# mdio_master_model: IP-XACT component
VLNV IcronTechnologies:IcronTechnologies:mdio_master_model:1.0

## Parameters
addr_width = 8
bus_width = 32

## Bus interfaces (logical=physical port)
default_map: slave AGNISYS:AGNISYS:APB:1.0, memory map mdio_mastermap
  pclk=pclk, presetn=presetn, psel=psel, penable=penable, pwrite=pwrite, pprot=pprot, pstrb=pstrb, pwdata=pwdata, paddr=paddr, pready=pready, prdata=prdata, pslverr=pslverr

## Ports
in pclk
in presetn
in psel
in penable
in pwrite
in pprot[2:0]
in pstrb[(bus_width div 8 )-1:0]
in pwdata[bus_width -1:0]
in paddr[addr_width -1:0]
out pready
out prdata[bus_width -1:0]
out pslverr
out mdio_master_regsversion_major_r[7:0]
out mdio_master_regsversion_minor_r[7:0]
out mdio_master_regsversion_patch_r[7:0]
out mdio_master_regstiming_enb
out mdio_master_regstiming_hold_clks_r[7:0]
out mdio_master_regstiming_setup_clks_r[7:0]
out mdio_master_regstiming_half_mdc_clks_r[7:0]
out mdio_master_regscontrol_enb
out mdio_master_regscontrol_phyad_r[4:0]
out mdio_master_regscontrol_regad_r[4:0]
out mdio_master_regscontrol_op_r[1:0]
out mdio_master_regscontrol_st_r[1:0]
out mdio_master_regscontrol_go_r
in mdio_master_regscontrol_go_hw_clear
out mdio_master_regswr_data_enb
out mdio_master_regswr_data_wr_data_r[15:0]
in mdio_master_regsrd_data_rd_data_in[15:0]
in mdio_master_regsrd_data_rd_data_in_enb

## Address spaces and blocks
mdio_mastermap.mdio_master: base 0x000, range 0x100, width 32

## Registers
Registers are 32-bit, read-write, reset 0x0 unless marked. A register's access mark holds for its fields unless they carry their own. Offsets are from the block's base; lines under a group give offsets from that group; [hi:lo] are bit positions; {n}, {i} and the like mark numbered series; 'fields as' and 'values as' point back to an identical list; <NAME> marks a mode.

## mdio_mastermap.mdio_master — MDIO Master
Base 0x00000000
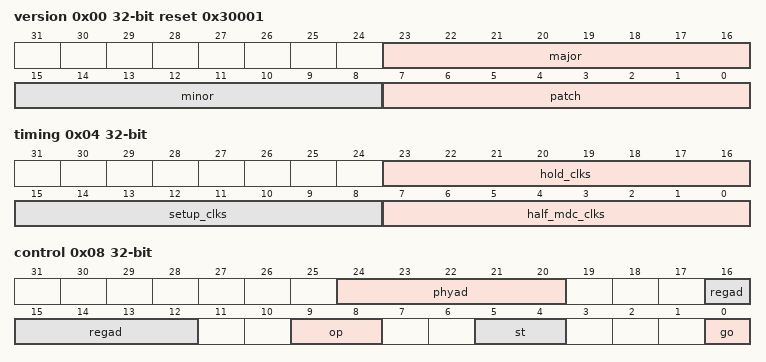
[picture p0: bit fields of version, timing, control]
0x00 version ro reset 0x30001
  [23:16] major — Major version
  [15:8] minor — Minor version
  [7:0] patch — Patch version
0x04 timing — MDIO timing
  [23:16] hold_clks — Hold time in clock cycles
  [15:8] setup_clks — Setup time in clock cycles
  [7:0] half_mdc_clks — Half MDC period in clock cycles
0x08 control — MDIO control
  [24:20] phyad — PHY Address
  [16:12] regad — Register Address (ST <01>) / Device Type (ST <00>)
  [9:8] op — Operation Code: ST <00>: 2'b00 : Address 2'b01 : Write 2'b10 : Post-Read-Increment-Address 2'b11 : Read ST <01>: 2'b00 : Reserved 2'b01 : Write 2'b10 : Read 2'b11 : Reserved
  [5:4] st — Start of Frame pattern: 2'b00 : Clause 45 of IEEE 802.3 (Indirect Address) 2'b01 : Clause 22 of IEEE 802.3 (Direct Address)
  [0] go — Write a 1 to initiate an MDIO transaction. HW will clear this field upon completion and also generates an interrupt. A new transaction should not be attempted until this field returns a 0, indicating it is not busy.
0x0C wr_data — MDIO write data
  [15:0] wr_data — MDIO Write Data
0x10 rd_data ro — MDIO read data
  [15:0] rd_data — MDIO Read Data
0x14 irq group — MDIO Master Interrupt register group
  0x00 enable — Interrupt Enable register - Write 1 to enable, 0 to mask an interrupt
    [0] done — Transfer done
  0x04 pending — Pending register - This indicates which events are pending, Write 1 to clear
    [0] done write-1-clears — Edge-triggered - Active High Transfer done
  0x08 pending_irq ro — Interrupt Pending register - This indicates which pending events are enabled to cause an interrupt
    [0] done — Edge-triggered - Active High Transfer done
  0x0C raw ro — This register contains the registered state of interrupt signals
    [0] done — Current state of the transfer done flag (Active-High)
